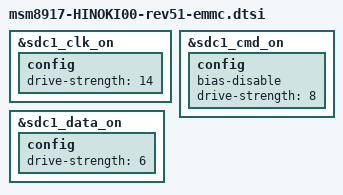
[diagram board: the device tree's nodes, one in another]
/*
 * This software is contributed or developed by KYOCERA Corporation.
 * (C) 2020 KYOCERA Corporation
 *
 * This program is free software; you can redistribute it and/or modify
 * it under the terms of the GNU General Public License version 2 and
 * only version 2 as published by the Free Software Foundation.
 *
 * This program is distributed in the hope that it will be useful,
 * but WITHOUT ANY WARRANTY; without even the implied warranty of
 * MERCHANTABILITY or FITNESS FOR A PARTICULAR PURPOSE.  See the
 * GNU General Public License for more details.
 */
/* msm8937-pinctrl.dtsi */

&sdc1_clk_on {
	config{
		drive-strength = <14>; /* 14 MA */
	};
};


&sdc1_cmd_on {
	config{
		/delete-property/ bias-pull-up;
		bias-disable;/*No pull*/
		drive-strength = <8>; /* 8 MA */
	};
};

&sdc1_data_on {
	config{
		drive-strength = <6>; /* 6 MA */
	};
};
